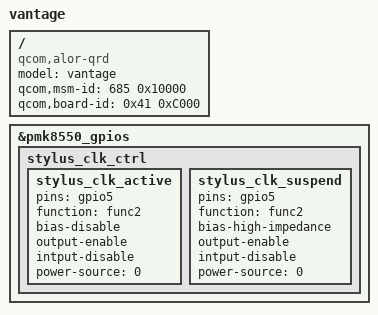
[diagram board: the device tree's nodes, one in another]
// SPDX-License-Identifier: BSD-3-Clause
/*
 * Copyright (c) 2025 Qualcomm Innovation Center, Inc. All rights reserved.
 */

/dts-v1/;
/plugin/;

#include "alor-vantage-products-common-overlay.dtsi"

/ {
	model = "vantage";
	compatible = "qcom,alor-qrd", "qcom,alor", "qcom,qrd";
	qcom,msm-id = <685 0x10000>;
	qcom,board-id = <0x41 0xC000>;
};

&pmk8550_gpios {
	stylus_clk_ctrl {
		stylus_clk_active: stylus_clk_active {
			pins = "gpio5";
			function = "func2";
			bias-disable; // No Pull
			output-enable; // digital output, no invert
			intput-disable; // prevent GPIO from being set to DIO
			power-source = <0>;
		};
		stylus_clk_suspend: stylus_clk_suspend {
			pins = "gpio5";
			function = "func2";
			bias-high-impedance;
			output-enable; // digital output, no invert
			intput-disable; // prevent GPIO from being set to DIO
			power-source = <0>;
		};
	};
};
